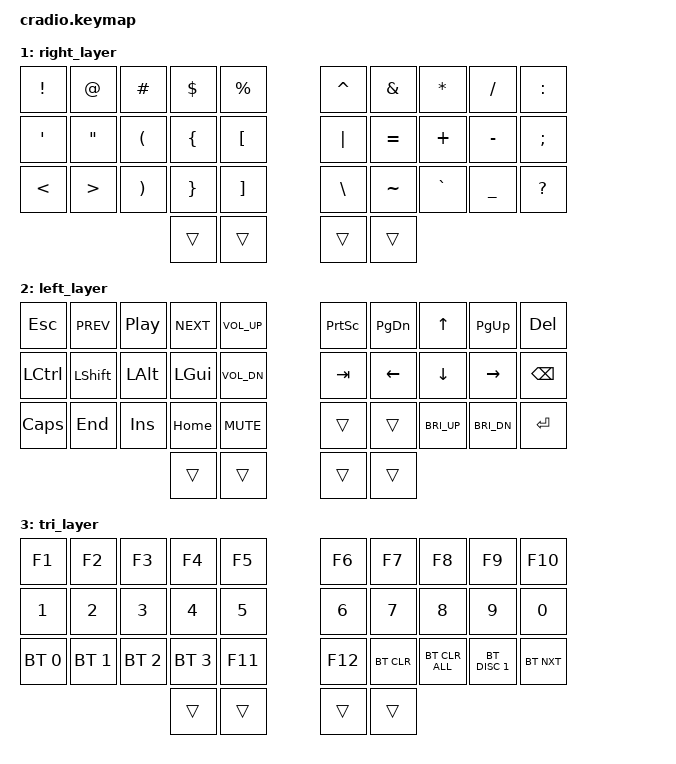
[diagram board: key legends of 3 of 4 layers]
// Copyright (c) 2022 The ZMK Contributors
// SPDX-License-Identifier: MIT

#include <behaviors.dtsi>
#include <dt-bindings/zmk/keys.h>
#include <dt-bindings/zmk/bt.h>

// Home row mods macro
#define HRML(k1,k2,k3,k4) &ht LCTRL k1  &ht LSHFT k2  &ht LALT k3  &ht LGUI k4
#define HRMR(k1,k2,k3,k4) &ht RGUI k1  &ht RALT k2  &ht RSHFT k3  &ht RCTRL k4

/ {
    behaviors {
        ht: hold_tap {
            compatible = "zmk,behavior-hold-tap";
            #binding-cells = <2>;
            flavor = "tap-preferred";
            tapping-term-ms = <220>;
            quick-tap-ms = <150>;
            require-prior-idle-ms = <100>;
            bindings = <&kp>, <&kp>;
        };
    };

    conditional_layers {
        compatible = "zmk,conditional-layers";
        tri_layer {
            if-layers = <1 2>;
            then-layer = <3>;
        };
    };

    keymap {
        compatible = "zmk,keymap";
        default_layer {
            bindings = <
        //╭──────────┬──────────┬──────────┬──────────┬──────────╮   ╭──────────┬──────────┬──────────┬──────────┬──────────╮
        //│  Q       │  W       │  F       │  P       │  B       │   │  J       │  L       │  U       │  Y       │  ;       │
            &kp Q      &kp W      &kp F      &kp P      &kp B          &kp J      &kp L      &kp U      &kp Y      &kp SEMI
        //├──────────┼──────────┼──────────┼──────────┼──────────┤   ├──────────┼──────────┼──────────┼──────────┼──────────┤
        //│  A       │  R       │  S       │  T       │  G       │   │  M       │  N       │  E       │  I       │ O        │
            HRML(A,        R,         S,         T)     &kp G          &kp M      HRMR(N,        E,         I,        O)
        //├──────────┼──────────┼──────────┼──────────┼──────────┤   ├──────────┼──────────┼──────────┼──────────┼──────────┤
        //│  X       │  C       │  D       │  V       │  Z       │   │  K       │  H       │ ,        │ .        │   ?      │
            &kp X      &kp C      &kp D      &kp V      &kp Z          &kp K      &kp H      &kp COMMA  &kp DOT    &kp FSLH
        //╰──────────┴──────────┴──────────┼──────────┼──────────┤   ├──────────┼──────────┼──────────┴──────────┴──────────╯
                                             &kp LSHIFT &mo 2          &kp SPACE  &mo 1 
        //                                 ╰──────────┴──────────╯   ╰──────────┴──────────╯
            >;
        };

        right_layer {
            bindings = <
        //╭──────────┬──────────┬──────────┬──────────┬──────────╮   ╭──────────┬──────────┬──────────┬──────────┬──────────╮
        //│  !       │  @       │  #       │  $       │  %       │   │  ^       │  &       │   *      │  /       │  :       │
            &kp EXCL   &kp AT     &kp HASH   &kp DLLR   &kp PRCNT      &kp CARET  &kp AMPS   &kp ASTRK  &kp FSLH   &kp COLON
        //├──────────┼──────────┼──────────┼──────────┼──────────┤   ├──────────┼──────────┼──────────┼──────────┼──────────┤
        //│ '        │  "       │          │          │          │   │  |       │  =       │  +       │  -       │  ;       │
            &kp SQT    &kp DQT    &kp LPAR   &kp LBRC   &kp LBKT       &kp PIPE   &kp EQUAL  &kp PLUS   &kp MINUS  &kp SEMI
        //├──────────┼──────────┼──────────┼──────────┼──────────┤   ├──────────┼──────────┼──────────┼──────────┼──────────┤
        //│          │          │          │          │          │   │  \       │  ~       │  `       │  _       │  ?       │
            &kp LT     &kp GT     &kp RPAR   &kp RBRC   &kp RBKT       &kp BSLH   &kp TILDE  &kp GRAVE  &kp UNDER  &kp QMARK
        //╰──────────┴──────────┴──────────┼──────────┼──────────┤   ├──────────┼──────────┼──────────┴──────────┴──────────╯
                                             &trans     &trans         &trans     &trans
        //                                 ╰──────────┴──────────╯   ╰──────────┴──────────╯
            >;
        };

        left_layer {
            bindings = <
        //╭──────────┬──────────┬──────────┬──────────┬──────────╮   ╭──────────┬──────────┬──────────┬──────────┬──────────╮
        //│ Escape   │          │          │          │          │   │          │          │          │          │  Delete  │
            &kp ESC   &kp C_PREV   &kp C_PP  &kp C_NEXT &kp C_VOL_UP   &kp PSCRN  &kp PG_DN   &kp UP    &kp PG_UP   &kp DEL
        //├──────────┼──────────┼──────────┼──────────┼──────────┤   ├──────────┼──────────┼──────────┼──────────┼──────────┤
        //│          │          │          │          │          │   │  TAB     │          │          │          │  back    │
           &kp LCTRL  &kp LSHIFT  &kp LALT   &kp LGUI  &kp C_VOL_DN   &kp TAB    &kp LEFT  &kp DOWN   &kp RIGHT   &kp BSPC
        //├──────────┼──────────┼──────────┼──────────┼──────────┤   ├──────────┼──────────┼──────────┼──────────┼──────────┤
        //│          │          │          │          │          │   │          │          │          │          │          │
            &kp CAPS  &kp END   &kp INS     &kp HOME  &kp C_MUTE      &trans     &trans  &kp C_BRI_UP &kp C_BRI_DN  &kp RET
        //╰──────────┴──────────┴──────────┼──────────┼──────────┤   ├──────────┼──────────┼──────────┴──────────┴──────────╯
                                             &trans     &trans         &trans     &trans
        //                                 ╰──────────┴──────────╯   ╰──────────┴──────────╯
            >;
        };

        tri_layer {
            bindings = <
        //╭──────────┬──────────┬──────────┬──────────┬──────────╮   ╭──────────┬──────────┬──────────┬──────────┬──────────╮
        //│          │          │          │          │          │   │          │          │          │          │          │
           &kp F1       &kp F2     &kp F3     &kp F4    &kp F5         &kp F6     &kp F7     &kp F8    &kp F9    &kp F10
        //├──────────┼──────────┼──────────┼──────────┼──────────┤   ├──────────┼──────────┼──────────┼──────────┼──────────┤
        //│          │          │          │          │          │   │          │          │          │          │          
            &kp N1  &kp N2     &kp N3       &kp N4    &kp N5           &kp N6        &kp N7     &kp N8     &kp N9    &kp N0
        //├──────────┼──────────┼──────────┼──────────┼──────────┤   ├──────────┼──────────┼──────────┼──────────┼──────────┤
        //│          │          │          │          │          │   │          │          │          │          │          │
         &bt BT_SEL 0 &bt BT_SEL 1 &bt BT_SEL 2 &bt BT_SEL 3 &kp F11    &kp F12  &bt BT_CLR &bt BT_CLR_ALL &bt BT_DISC 1 &bt BT_NXT
        //╰──────────┴──────────┴──────────┼──────────┼──────────┤   ├──────────┼──────────┼──────────┴──────────┴──────────╯
                                             &trans     &trans         &trans     &trans
        //                                 ╰──────────┴──────────╯   ╰──────────┴──────────╯
            >;
        };
    };
};
